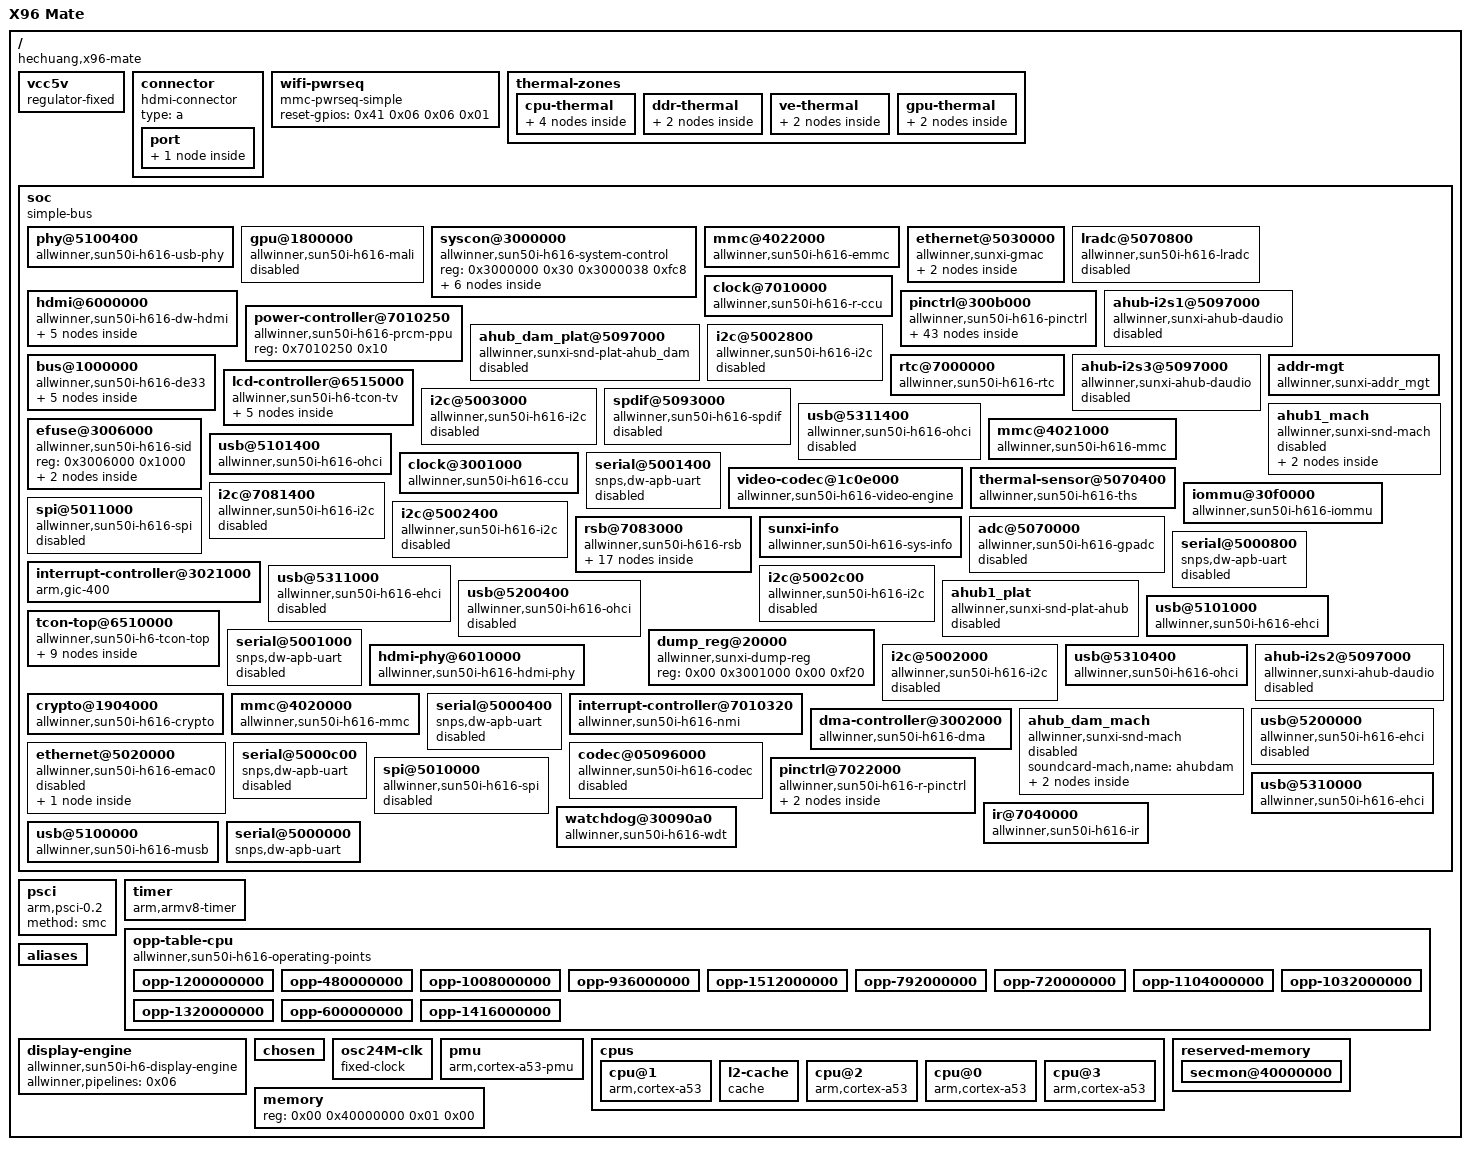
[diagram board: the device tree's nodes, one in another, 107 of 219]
/dts-v1/;

/ {
	#address-cells = <0x02>;
	model = "X96 Mate";
	serial-number = "32c0500063aacc40";
	#size-cells = <0x02>;
	interrupt-parent = <0x01>;
	compatible = "hechuang,x96-mate\0allwinner,sun50i-h616";

	vcc5v {
		regulator-max-microvolt = <0x4c4b40>;
		regulator-always-on;
		regulator-min-microvolt = <0x4c4b40>;
		regulator-name = "vcc-5v";
		compatible = "regulator-fixed";
		phandle = <0x33>;
	};

	connector {
		type = "a";
		compatible = "hdmi-connector";

		port {

			endpoint {
				remote-endpoint = <0x36>;
				phandle = <0x27>;
			};
		};
	};

	wifi-pwrseq {
		reset-gpios = <0x41 0x06 0x06 0x01>;
		compatible = "mmc-pwrseq-simple";
		phandle = <0xa9>;
	};

	thermal-zones {

		cpu-thermal {
			polling-delay = <0x3e8>;
			polling-delay-passive = <0x1f4>;
			thermal-sensors = <0x34 0x02>;
			sustainable-power = <0x3e8>;

			trips {

				cpu-trip-2 {
					temperature = <0x1adb0>;
					hysteresis = <0x00>;
					type = "critical";
					phandle = <0xa5>;
				};

				cpu-trip-0 {
					temperature = <0xea60>;
					hysteresis = <0x00>;
					type = "passive";
					phandle = <0xa3>;
				};

				cpu-trip-1 {
					temperature = <0x11170>;
					hysteresis = <0x00>;
					type = "passive";
					phandle = <0xa4>;
				};
			};
		};

		ddr-thermal {
			polling-delay = <0x00>;
			polling-delay-passive = <0x00>;
			thermal-sensors = <0x34 0x03>;

			trips {

				ddr-trip-0 {
					temperature = <0x1adb0>;
					hysteresis = <0x00>;
					type = "critical";
					phandle = <0xa8>;
				};
			};
		};

		ve-thermal {
			polling-delay = <0x00>;
			polling-delay-passive = <0x00>;
			thermal-sensors = <0x34 0x01>;

			trips {

				ve-trip-0 {
					temperature = <0x1adb0>;
					hysteresis = <0x00>;
					type = "critical";
					phandle = <0xa7>;
				};
			};
		};

		gpu-thermal {
			polling-delay = <0x3e8>;
			polling-delay-passive = <0x1f4>;
			thermal-sensors = <0x34 0x00>;
			sustainable-power = <0x44c>;

			trips {

				gpu-trip-0 {
					temperature = <0x1adb0>;
					hysteresis = <0x00>;
					type = "critical";
					phandle = <0xa6>;
				};
			};
		};
	};

	soc {
		#address-cells = <0x01>;
		#size-cells = <0x01>;
		compatible = "simple-bus";
		ranges = <0x00 0x00 0x00 0x40000000>;

		phy@5100400 {
			clock-names = "usb0_phy\0usb1_phy\0usb2_phy\0usb3_phy\0pmu2_clk";
			reg-names = "phy_ctrl\0pmu0\0pmu1\0pmu2\0pmu3";
			resets = <0x02 0x26 0x02 0x27 0x02 0x28 0x02 0x29>;
			clocks = <0x02 0x61 0x02 0x63 0x02 0x65 0x02 0x67 0x02 0x6e>;
			#phy-cells = <0x01>;
			compatible = "allwinner,sun50i-h616-usb-phy";
			status = "okay";
			reg = <0x5100400 0x24 0x5101800 0x14 0x5200800 0x14 0x5310800 0x14 0x5311800 0x14>;
			phandle = <0x24>;
			reset-names = "usb0_reset\0usb1_reset\0usb2_reset\0usb3_reset";
		};

		gpu@1800000 {
			power-domains = <0x0e 0x02>;
			clock-names = "core\0bus";
			resets = <0x02 0x03>;
			interrupts = <0x00 0x5f 0x04 0x00 0x60 0x04 0x00 0x61 0x04>;
			clocks = <0x02 0x23 0x02 0x24>;
			compatible = "allwinner,sun50i-h616-mali\0arm,mali-bifrost";
			status = "disabled";
			interrupt-names = "job\0mmu\0gpu";
			reg = <0x1800000 0x40000>;
			phandle = <0x39>;
		};

		syscon@3000000 {
			#address-cells = <0x01>;
			#size-cells = <0x01>;
			compatible = "allwinner,sun50i-h616-system-control";
			ranges;
			reg = <0x3000000 0x30 0x3000038 0xfc8>;
			phandle = <0x1a>;

			sram@1a00000 {
				#address-cells = <0x01>;
				#size-cells = <0x01>;
				compatible = "mmio-sram";
				ranges = <0x00 0x1a00000 0x200000>;
				reg = <0x1a00000 0x200000>;
				phandle = <0x3e>;

				sram-section@0 {
					compatible = "allwinner,sun50i-h616-sram-c1";
					reg = <0x00 0x200000>;
					phandle = <0x10>;
				};
			};

			sram@100000 {
				#address-cells = <0x01>;
				#size-cells = <0x01>;
				compatible = "mmio-sram";
				ranges = <0x00 0x100000 0x18000>;
				reg = <0x100000 0x18000>;
				phandle = <0x3b>;

				scpi-sram@17c00 {
					compatible = "arm,scp-shmem";
					reg = <0x17c00 0x200>;
					phandle = <0x3c>;
				};
			};

			sram@28000 {
				#address-cells = <0x01>;
				#size-cells = <0x01>;
				compatible = "mmio-sram";
				ranges = <0x00 0x28000 0x30000>;
				reg = <0x28000 0x30000>;
				phandle = <0x3d>;

				sram-section@0 {
					compatible = "allwinner,sun50i-h616-sram-c\0allwinner,sun50i-a64-sram-c";
					reg = <0x00 0x1e000>;
					phandle = <0x0b>;
				};
			};
		};

		mmc@4022000 {
			mmc-ddr-3_3v;
			pinctrl-names = "default";
			#address-cells = <0x01>;
			pinctrl-0 = <0x15>;
			clock-names = "ahb\0mmc";
			cap-sd-highspeed;
			vqmmc-supply = <0x16>;
			mmc-hs200-1_8v;
			bus-width = <0x08>;
			non-removable;
			resets = <0x02 0x10>;
			cap-sdio-irq;
			interrupts = <0x00 0x25 0x04>;
			clocks = <0x02 0x41 0x02 0x3e>;
			#size-cells = <0x00>;
			vmmc-supply = <0x13>;
			cap-mmc-hw-reset;
			mmc-ddr-1_8v;
			compatible = "allwinner,sun50i-h616-emmc\0allwinner,sun50i-a100-emmc";
			status = "okay";
			reg = <0x4022000 0x1000>;
			phandle = <0x68>;
			max-frequency = <0x8f0d180>;
			cap-mmc-highspeed;
			reset-names = "ahb";
		};

		ethernet@5030000 {
			rx-delay = <0x1f>;
			gmac-power1;
			pinctrl-names = "default";
			phy-supply = <0x1d>;
			phy-mode = "rmii";
			phy-rst;
			tx-delay = <0x07>;
			pinctrl-0 = <0x1b>;
			clock-names = "bus-emac1\0emac-25m";
			reg-names = "gmac1_reg\0ephy_reg";
			local-mac-address = [02 00 63 aa cc 40];
			resets = <0x02 0x1f>;
			interrupts = <0x00 0x0f 0x04>;
			clocks = <0x02 0x53 0x02 0x51>;
			gmac-power2;
			gmac-power0;
			compatible = "allwinner,sunxi-gmac";
			status = "okay";
			interrupt-names = "gmacirq";
			reg = <0x5030000 0x10000 0x3000034 0x04>;
			phandle = <0x78>;
			allwinner,tx-delay-ps = <0x2bc>;
			phy-handle = <0x1c>;
			reset-names = "stmmaceth";
			allwinner,rx-delay-ps = <0xc1c>;

			mdio {
				#address-cells = <0x01>;
				#size-cells = <0x00>;
				compatible = "ethernet-phy-ieee802.3-c22";
				phandle = <0x79>;

				ethernet-phy@1 {
					compatible = "ethernet-phy-ieee802.3-c22";
					reg = <0x01>;
					phandle = <0x1c>;
				};
			};
		};

		lradc@5070800 {
			resets = <0x02 0x3b>;
			interrupts = <0x00 0x14 0x04>;
			clocks = <0x02 0x71>;
			compatible = "allwinner,sun50i-h616-lradc\0allwinner,sun50i-r329-lradc";
			status = "disabled";
			reg = <0x5070800 0x400>;
			phandle = <0x7c>;
		};

		hdmi@6000000 {
			reg-io-width = <0x01>;
			phy-names = "phy";
			clock-names = "iahb\0isfr\0tmds\0cec\0hdcp\0hdcp-bus";
			hvcc-supply = <0x16>;
			resets = <0x02 0x33 0x02 0x3a>;
			interrupts = <0x00 0x3f 0x04>;
			clocks = <0x02 0x75 0x02 0x73 0x02 0x72 0x02 0x74 0x02 0x7e 0x02 0x7f>;
			#sound-dai-cells = <0x00>;
			compatible = "allwinner,sun50i-h616-dw-hdmi\0allwinner,sun50i-h6-dw-hdmi";
			status = "okay";
			phys = <0x25>;
			reg = <0x6000000 0x10000>;
			phandle = <0x23>;
			reset-names = "ctrl\0hdcp";

			ports {
				#address-cells = <0x01>;
				#size-cells = <0x00>;

				port@0 {
					reg = <0x00>;
					phandle = <0x8d>;

					endpoint {
						remote-endpoint = <0x26>;
						phandle = <0x2b>;
					};
				};

				port@1 {
					reg = <0x01>;
					phandle = <0x8e>;

					endpoint {
						remote-endpoint = <0x27>;
						phandle = <0x36>;
					};
				};
			};
		};

		clock@7010000 {
			#reset-cells = <0x01>;
			clock-names = "hosc\0losc\0iosc\0pll-periph";
			clocks = <0x11 0x0f 0x00 0x0f 0x02 0x02 0x04>;
			#clock-cells = <0x01>;
			compatible = "allwinner,sun50i-h616-r-ccu";
			reg = <0x7010000 0x210>;
			phandle = <0x2f>;
		};

		pinctrl@300b000 {
			clock-names = "apb\0hosc\0losc";
			gpio-controller;
			interrupts = <0x00 0x33 0x04 0x00 0x34 0x04 0x00 0x35 0x04 0x00 0x2b 0x04 0x00 0x36 0x04 0x00 0x37 0x04 0x00 0x38 0x04 0x00 0x39 0x04>;
			clocks = <0x02 0x1a 0x11 0x0f 0x00>;
			compatible = "allwinner,sun50i-h616-pinctrl";
			#interrupt-cells = <0x03>;
			reg = <0x300b000 0x400>;
			phandle = <0x41>;
			#gpio-cells = <0x03>;
			interrupt-controller;

			i2c4-ph-pins {
				function = "i2c4";
				pins = "PH6\0PH7";
				phandle = <0x4a>;
			};

			pwm2-ph-pin {
				function = "pwm2";
				pins = "PH2";
				phandle = <0x50>;
			};

			pwm3-ph-pin {
				function = "pwm3";
				pins = "PH0";
				phandle = <0x51>;
			};

			uart2-pg-pins {
				function = "uart2";
				pins = "PG15\0PG16";
				phandle = <0x5c>;
			};

			pwm4-ph-pin {
				function = "pwm4";
				pins = "PH1";
				phandle = <0x52>;
			};

			spi1-cs0-pin {
				function = "spi1";
				pins = "PH5";
				phandle = <0x57>;
			};

			i2c1-pi-pins {
				function = "i2c1";
				pins = "PI7\0PI8";
				phandle = <0x43>;
			};

			i2c4-pg-pins {
				function = "i2c4";
				pins = "PG15\0PG16";
				phandle = <0x49>;
			};

			uart5-pins {
				function = "uart5";
				pins = "PH2\0PH3";
				phandle = <0x63>;
			};

			rmii-pins {
				function = "emac1";
				pins = "PA0\0PA1\0PA2\0PA3\0PA4\0PA5\0PA6\0PA7\0PA8\0PA9";
				drive-strength = <0x28>;
				phandle = <0x1b>;
			};

			pwm1-pi-pin {
				function = "pwm1";
				pins = "PI11";
				phandle = <0x4f>;
			};

			pwm5-pin {
				function = "pwm5";
				pins = "PA12";
				phandle = <0x53>;
				bias-pull-up;
			};

			mmc2-pins {
				function = "mmc2";
				pins = "PC0\0PC1\0PC5\0PC6\0PC8\0PC9\0PC10\0PC11\0PC13\0PC14\0PC15\0PC16";
				drive-strength = <0x1e>;
				phandle = <0x15>;
				bias-pull-up;
			};

			uart3-pi-pins {
				function = "uart3";
				pins = "PI9\0PI10";
				phandle = <0x60>;
			};

			uart2-pg-rts-cts-pins {
				function = "uart2";
				pins = "PG17\0PG18";
				phandle = <0x5d>;
			};

			spi1-cs1-pin {
				function = "spi1";
				pins = "PH9";
				phandle = <0x58>;
			};

			ir-rx-pin {
				function = "ir_rx";
				pins = "PH10";
				phandle = <0x30>;
			};

			mmc1-pins {
				function = "mmc1";
				pins = "PG0\0PG1\0PG2\0PG3\0PG4\0PG5";
				drive-strength = <0x1e>;
				phandle = <0x14>;
				bias-pull-up;
			};

			i2c3-ph-pins {
				function = "i2c3";
				pins = "PH4\0PH5";
				phandle = <0x48>;
			};

			uart1-rts-cts-pins {
				function = "uart1";
				pins = "PG8\0PG9";
				phandle = <0x5a>;
			};

			i2c3-pa-pins {
				function = "i2c3";
				pins = "PA10\0PA11";
				phandle = <0x46>;
				bias-pull-up;
			};

			rgmii-pins {
				function = "emac0";
				pins = "PI0\0PI1\0PI2\0PI3\0PI4\0PI5\0PI7\0PI8\0PI9\0PI10\0PI11\0PI12\0PI13\0PI14\0PI15";
				drive-strength = <0x28>;
				phandle = <0x42>;
			};

			mmc0-pins {
				function = "mmc0";
				pins = "PF0\0PF1\0PF2\0PF3\0PF4\0PF5";
				drive-strength = <0x1e>;
				phandle = <0x12>;
				bias-pull-up;
			};

			spi0-cs0-pin {
				function = "spi0";
				pins = "PC3";
				phandle = <0x55>;
			};

			i2c3-pg-pins {
				function = "i2c3";
				pins = "PG17\0PG18";
				phandle = <0x47>;
			};

			x32clk-fanout-pin {
				function = "clock";
				pins = "PG10";
				phandle = <0x64>;
			};

			spi1-pins {
				function = "spi1";
				pins = "PH6\0PH7\0PH8";
				phandle = <0x56>;
			};

			i2s3-pins {
				function = "i2s3";
				pins = "PH5\0PH6\0PH7\0PH8\0PH9";
				phandle = <0x4c>;
			};

			uart2-ph-rts-cts-pins {
				function = "uart2";
				pins = "PH7\0PH8";
				phandle = <0x5f>;
			};

			pwm1-pg-pin {
				function = "pwm1";
				pins = "PG19";
				phandle = <0x4d>;
			};

			i2c2-pi-pins {
				function = "i2c2";
				pins = "PI9\0PI10";
				phandle = <0x45>;
			};

			uart4-pi-rts-cts-pins {
				function = "uart4";
				pins = "PI15\0PI16";
				phandle = <0x62>;
			};

			i2c0-pins {
				function = "i2c0";
				pins = "PI5\0PI6";
				phandle = <0x19>;
			};

			uart2-pi-pins {
				function = "uart2";
				pins = "PI5\0PI6";
				phandle = <0x5b>;
			};

			uart0-ph-pins {
				function = "uart0";
				pins = "PH0\0PH1";
				phandle = <0x18>;
			};

			uart1-pins {
				function = "uart1";
				pins = "PG6\0PG7";
				phandle = <0x59>;
			};

			spi0-pins {
				function = "spi0";
				pins = "PC0\0PC2\0PC4";
				phandle = <0x54>;
			};

			i2s2-pins {
				function = "i2s2";
				pins = "PG10\0PG11\0PG12\0PG13\0PG14";
				phandle = <0x4b>;
			};

			i2c2-ph-pins {
				function = "i2c2";
				pins = "PH2\0PH3";
				phandle = <0x44>;
			};

			uart4-pi-pins {
				function = "uart4";
				pins = "PI13\0PI14";
				phandle = <0x61>;
			};

			uart2-ph-pins {
				function = "uart2";
				pins = "PH5\0PH6";
				phandle = <0x5e>;
			};

			pwm1-ph-pin {
				function = "pwm1";
				pins = "PH3";
				phandle = <0x4e>;
			};

			spdif-tx-pin {
				function = "spdif";
				pins = "PH4";
				phandle = <0x1e>;
			};
		};

		ahub-i2s1@5097000 {
			daudio_master = <0x04>;
			clock-names = "apb\0audio-codec-1x\0audio-codec-4x\0audio-hub";
			signal_inversion = <0x01>;
			mclk_div = <0x01>;
			clocks = <0x02 0x5f 0x02 0x5b 0x02 0x5c 0x02 0x5e>;
			pinconfig = <0x00>;
			#sound-dai-cells = <0x00>;
			frametype = <0x00>;
			compatible = "allwinner,sunxi-ahub-daudio";
			audio_format = <0x01>;
			slot_width_select = <0x20>;
			status = "disabled";
			tdm_num = <0x01>;
			reg = <0x5097000 0xadf>;
			phandle = <0x81>;
			tdm_config = <0x01>;
			pcm_lrck_period = <0x20>;
		};

		power-controller@7010250 {
			#power-domain-cells = <0x01>;
			compatible = "allwinner,sun50i-h616-prcm-ppu";
			reg = <0x7010250 0x10>;
			phandle = <0x0e>;
		};

		ahub_dam_plat@5097000 {
			clock-names = "clk_pll_audio\0clk_pll_audio_4x\0clk_audio_hub\0clk_bus_audio_hub";
			resets = <0x02 0x25>;
			clocks = <0x02 0x5b 0x02 0x5c 0x02 0x5e 0x02 0x5f>;
			#sound-dai-cells = <0x00>;
			compatible = "allwinner,sunxi-snd-plat-ahub_dam";
			status = "disabled";
			reg = <0x5097000 0x1000>;
			phandle = <0x20>;
		};

		bus@1000000 {
			#address-cells = <0x01>;
			allwinner,sram = <0x0b 0x01>;
			#size-cells = <0x01>;
			compatible = "allwinner,sun50i-h616-de33\0allwinner,sun50i-a64-de2";
			ranges = <0x00 0x1000000 0x400000>;
			reg = <0x1000000 0x400000>;

			mixer@100000 {
				clock-names = "bus\0mod";
				resets = <0x0c 0x00>;
				clocks = <0x0c 0x00 0x0c 0x06>;
				compatible = "allwinner,sun50i-h616-de33-mixer-0";
				reg = <0x100000 0x100000 0x8100 0x40 0x280000 0x20000>;
				phandle = <0x06>;

				ports {
					#address-cells = <0x01>;
					#size-cells = <0x00>;

					port@1 {
						reg = <0x01>;
						phandle = <0x38>;

						endpoint {
							remote-endpoint = <0x0d>;
							phandle = <0x28>;
						};
					};
				};
			};

			clock@8000 {
				#reset-cells = <0x01>;
				clock-names = "mod\0bus";
				resets = <0x02 0x01>;
				clocks = <0x02 0x1d 0x02 0x1e>;
				#clock-cells = <0x01>;
				compatible = "allwinner,sun50i-h616-de33-clk";
				reg = <0x8000 0x100>;
				phandle = <0x0c>;
			};
		};

		i2c@5002800 {
			#address-cells = <0x01>;
			resets = <0x02 0x19>;
			interrupts = <0x00 0x08 0x04>;
			clocks = <0x02 0x4a>;
			#size-cells = <0x00>;
			dma-names = "rx\0tx";
			compatible = "allwinner,sun50i-h616-i2c\0allwinner,sun8i-v536-i2c\0allwinner,sun6i-a31-i2c";
			status = "disabled";
			reg = <0x5002800 0x400>;
			phandle = <0x71>;
			dmas = <0x17 0x2d 0x17 0x2d>;
		};

		rtc@7000000 {
			clock-names = "bus\0hosc\0pll-32k";
			interrupts = <0x00 0x68 0x04>;
			clocks = <0x2f 0x0e 0x11 0x02 0x80>;
			#clock-cells = <0x01>;
			compatible = "allwinner,sun50i-h616-rtc";
			reg = <0x7000000 0x400>;
			phandle = <0x0f>;
		};

		ahub-i2s3@5097000 {
			daudio_master = <0x04>;
			clock-names = "apb\0audio-codec-1x\0audio-codec-4x\0audio-hub";
			signal_inversion = <0x01>;
			mclk_div = <0x04>;
			clocks = <0x02 0x5f 0x02 0x5b 0x02 0x5c 0x02 0x5e>;
			pinconfig = <0x01>;
			frametype = <0x00>;
			compatible = "allwinner,sunxi-ahub-daudio";
			audio_format = <0x01>;
			slot_width_select = <0x20>;
			status = "disabled";
			tdm_num = <0x03>;
			reg = <0x5097000 0xadf>;
			phandle = <0x83>;
			tdm_config = <0x01>;
			pcm_lrck_period = <0x20>;
		};

		addr-mgt {
			compatible = "allwinner,sunxi-addr_mgt";
			status = "okay";
			type_addr_eth = <0x02>;
			type_addr_wifi = <0x02>;
			phandle = <0xa2>;
			type_addr_bt = <0x02>;
		};

		lcd-controller@6515000 {
			clock-names = "ahb\0tcon-ch1";
			resets = <0x02 0x36>;
			interrupts = <0x00 0x42 0x04>;
			clocks = <0x02 0x79 0x2c 0x00>;
			compatible = "allwinner,sun50i-h6-tcon-tv\0allwinner,sun8i-r40-tcon-tv";
			reg = <0x6515000 0x1000>;
			phandle = <0x93>;
			reset-names = "lcd";

			ports {
				#address-cells = <0x01>;
				#size-cells = <0x00>;

				port@0 {
					reg = <0x00>;
					phandle = <0x94>;

					endpoint {
						remote-endpoint = <0x2d>;
						phandle = <0x29>;
					};
				};

				port@1 {
					#address-cells = <0x01>;
					#size-cells = <0x00>;
					reg = <0x01>;
					phandle = <0x95>;

					endpoint@1 {
						remote-endpoint = <0x2e>;
						reg = <0x01>;
						phandle = <0x2a>;
					};
				};
			};
		};

		i2c@5003000 {
			#address-cells = <0x01>;
			resets = <0x02 0x1b>;
			interrupts = <0x00 0x0a 0x04>;
			clocks = <0x02 0x4c>;
			#size-cells = <0x00>;
			dma-names = "rx\0tx";
			compatible = "allwinner,sun50i-h616-i2c\0allwinner,sun8i-v536-i2c\0allwinner,sun6i-a31-i2c";
			status = "disabled";
			reg = <0x5003000 0x400>;
			phandle = <0x73>;
			dmas = <0x17 0x2f 0x17 0x2f>;
		};

		spdif@5093000 {
			pinctrl-names = "default";
			pinctrl-0 = <0x1e>;
			clock-names = "apb\0spdif";
			resets = <0x02 0x22>;
			interrupts = <0x00 0x15 0x04>;
			clocks = <0x02 0x58 0x02 0x57>;
			dma-names = "tx";
			#sound-dai-cells = <0x00>;
			compatible = "allwinner,sun50i-h616-spdif";
			status = "disabled";
			reg = <0x5093000 0x400>;
			phandle = <0x7a>;
			dmas = <0x17 0x02>;
		};

		usb@5311400 {
			phy-names = "usb";
			resets = <0x02 0x2d>;
			interrupts = <0x00 0x21 0x04>;
			clocks = <0x02 0x6b 0x02 0x66>;
			compatible = "allwinner,sun50i-h616-ohci\0generic-ohci";
			status = "disabled";
			phys = <0x24 0x03>;
			reg = <0x5311400 0x100>;
			phandle = <0x8c>;
		};

		ahub1_mach {
			soundcard-mach,slot-num = <0x02>;
			soundcard-mach,slot-width = <0x20>;
			compatible = "allwinner,sunxi-snd-mach";
			status = "disabled";
			soundcard-mach,frame-master = <0x21>;
			phandle = <0x7f>;
			soundcard-mach,name = "HDMI";
			soundcard-mach,format = "i2s";
			soundcard-mach,bitclock-master = <0x21>;

			soundcard-mach,codec {
				phandle = <0x80>;
				sound-dai = <0x23>;
			};

			soundcard-mach,cpu {
				soundcard-mach,mclk-fs = <0x00>;
				soundcard-mach,pll-fs = <0x04>;
				phandle = <0x21>;
				sound-dai = <0x22>;
			};
		};

		efuse@3006000 {
			#address-cells = <0x01>;
			#size-cells = <0x01>;
			compatible = "allwinner,sun50i-h616-sid\0allwinner,sun50i-a64-sid";
			reg = <0x3006000 0x1000>;
			phandle = <0x3f>;

			thermal-sensor-calibration@14 {
				reg = <0x14 0x08>;
				phandle = <0x1f>;
			};

			cpu-speed-grade@0 {
				reg = <0x00 0x02>;
				phandle = <0x35>;
			};
		};

		mmc@4021000 {
			mmc-ddr-3_3v;
			pinctrl-names = "default";
			#address-cells = <0x01>;
			pinctrl-0 = <0x14>;
			clock-names = "ahb\0mmc";
			cap-sd-highspeed;
			vqmmc-supply = <0x13>;
			bus-width = <0x04>;
			non-removable;
			resets = <0x02 0x0f>;
			cap-sdio-irq;
			interrupts = <0x00 0x24 0x04>;
			clocks = <0x02 0x40 0x02 0x3d>;
			#size-cells = <0x00>;
			vmmc-supply = <0x13>;
			keep-power-in-suspend;
			compatible = "allwinner,sun50i-h616-mmc\0allwinner,sun50i-a100-mmc";
			status = "okay";
			mmc-pwrseq = <0xa9>;
			reg = <0x4021000 0x1000>;
			phandle = <0x67>;
			max-frequency = <0x2faf080>;
			cap-mmc-highspeed;
			reset-names = "ahb";
		};

		usb@5101400 {
			phy-names = "usb";
			resets = <0x02 0x2a>;
			interrupts = <0x00 0x1b 0x04>;
			clocks = <0x02 0x68 0x02 0x60>;
			compatible = "allwinner,sun50i-h616-ohci\0generic-ohci";
			status = "okay";
			phys = <0x24 0x00>;
			reg = <0x5101400 0x100>;
			phandle = <0x86>;
		};

		clock@3001000 {
			#reset-cells = <0x01>;
			clock-names = "hosc\0losc\0iosc";
			clocks = <0x11 0x0f 0x00 0x0f 0x02>;
			#clock-cells = <0x01>;
			compatible = "allwinner,sun50i-h616-ccu";
			reg = <0x3001000 0x1000>;
			phandle = <0x02>;
		};

		serial@5001400 {
			reg-io-width = <0x04>;
			resets = <0x02 0x16>;
			interrupts = <0x00 0x05 0x04>;
			clocks = <0x02 0x47>;
			dma-names = "tx\0rx";
			compatible = "snps,dw-apb-uart";
			status = "disabled";
			reg = <0x5001400 0x400>;
			phandle = <0x6e>;
			dmas = <0x17 0x13 0x17 0x13>;
			reg-shift = <0x02>;
		};

		video-codec@1c0e000 {
			clock-names = "ahb\0mod\0ram";
			allwinner,sram = <0x10 0x01>;
			resets = <0x02 0x05>;
			interrupts = <0x00 0x5d 0x04>;
			clocks = <0x02 0x29 0x02 0x28 0x02 0x33>;
			compatible = "allwinner,sun50i-h616-video-engine";
			reg = <0x1c0e000 0x2000>;
		};

		thermal-sensor@5070400 {
			nvmem-cells = <0x1f>;
			clock-names = "bus";
			allwinner,sram = <0x1a>;
			resets = <0x02 0x21>;
			interrupts = <0x00 0x13 0x04>;
			clocks = <0x02 0x56>;
			#thermal-sensor-cells = <0x01>;
			compatible = "allwinner,sun50i-h616-ths";
			nvmem-cell-names = "calibration";
			reg = <0x5070400 0x400>;
			phandle = <0x34>;
		};

		i2c@7081400 {
			pinctrl-names = "default";
			#address-cells = <0x01>;
			pinctrl-0 = <0x31>;
			resets = <0x2f 0x04>;
			interrupts = <0x00 0x69 0x04>;
			clocks = <0x2f 0x08>;
			#size-cells = <0x00>;
			dma-names = "rx\0tx";
			compatible = "allwinner,sun50i-h616-i2c\0allwinner,sun8i-v536-i2c\0allwinner,sun6i-a31-i2c";
			status = "disabled";
			reg = <0x7081400 0x400>;
			phandle = <0x99>;
			dmas = <0x17 0x30 0x17 0x30>;
		};

		iommu@30f0000 {
			resets = <0x02 0x0b>;
			interrupts = <0x00 0x3d 0x04>;
			clocks = <0x02 0x30>;
			#iommu-cells = <0x01>;
			compatible = "allwinner,sun50i-h616-iommu\0allwinner,sun50i-h6-iommu";
			reg = <0x30f0000 0x10000>;
			phandle = <0x65>;
		};

		i2c@5002400 {
			#address-cells = <0x01>;
			resets = <0x02 0x18>;
			interrupts = <0x00 0x07 0x04>;
			clocks = <0x02 0x49>;
			#size-cells = <0x00>;
			dma-names = "rx\0tx";
			compatible = "allwinner,sun50i-h616-i2c\0allwinner,sun8i-v536-i2c\0allwinner,sun6i-a31-i2c";
			status = "disabled";
			reg = <0x5002400 0x400>;
			phandle = <0x70>;
			dmas = <0x17 0x2c 0x17 0x2c>;
		};

		rsb@7083000 {
			pinctrl-names = "default";
			#address-cells = <0x01>;
			pinctrl-0 = <0x32>;
			resets = <0x2f 0x07>;
			interrupts = <0x00 0x6d 0x04>;
			clocks = <0x2f 0x0d>;
			#size-cells = <0x00>;
			clock-frequency = <0x2dc6c0>;
			compatible = "allwinner,sun50i-h616-rsb\0allwinner,sun8i-a23-rsb";
			status = "okay";
			reg = <0x7083000 0x400>;
			phandle = <0x9a>;

			pmic@745 {
				vina-supply = <0x33>;
				vinb-supply = <0x33>;
				vinc-supply = <0x33>;
				vind-supply = <0x33>;
				vine-supply = <0x33>;
				bldoin-supply = <0x33>;
				compatible = "x-powers,axp305\0x-powers,axp805\0x-powers,axp806";
				#interrupt-cells = <0x01>;
				reg = <0x745>;
				phandle = <0x9b>;
				cldoin-supply = <0x33>;
				aldoin-supply = <0x33>;
				x-powers,self-working-mode;
				interrupt-controller;

				regulators {

					aldo3 {
						regulator-max-microvolt = <0x325aa0>;
						regulator-min-microvolt = <0x325aa0>;
						regulator-name = "vcc3v3-ext2";
						status = "disabled";
						phandle = <0x9d>;
					};

					cldo2 {
					};

					dcdcc {
						regulator-max-microvolt = <0xf1b30>;
						regulator-always-on;
						regulator-min-microvolt = <0xc5c10>;
						regulator-name = "vdd-gpu-sys";
						phandle = <0x9f>;
					};

					aldo1 {
						regulator-max-microvolt = <0x325aa0>;
						regulator-always-on;
						regulator-min-microvolt = <0x325aa0>;
						regulator-name = "vcc-sys";
						phandle = <0x1d>;
					};

					dcdca {
						regulator-max-microvolt = <0x10c8e0>;
						regulator-always-on;
						regulator-min-microvolt = <0xc5c10>;
						regulator-name = "vdd-cpu";
						phandle = <0x05>;
					};

					bldo3 {
					};

					bldo1 {
						regulator-max-microvolt = <0x1b7740>;
						regulator-always-on;
						regulator-min-microvolt = <0x1b7740>;
						regulator-name = "vcc1v8";
						phandle = <0x16>;
					};

					sw {
					};

					cldo3 {
					};

					dcdcd {
						regulator-max-microvolt = <0x14c080>;
						regulator-always-on;
						regulator-min-microvolt = <0x14c080>;
						regulator-name = "vdd-dram";
						phandle = <0xa0>;
					};

					aldo2 {
						regulator-max-microvolt = <0x325aa0>;
						regulator-min-microvolt = <0x325aa0>;
						regulator-name = "vcc3v3-ext";
						status = "disabled";
						phandle = <0x9c>;
					};

					cldo1 {
						regulator-max-microvolt = <0x2625a0>;
						regulator-min-microvolt = <0x2625a0>;
						regulator-name = "vcc2v5";
					};

					bldo4 {
					};

					bldo2 {
						regulator-max-microvolt = <0x1b7740>;
						regulator-min-microvolt = <0x1b7740>;
						regulator-name = "vcc1v8-2";
						status = "disabled";
						phandle = <0x9e>;
					};

					dcdce {
						regulator-max-microvolt = <0x325aa0>;
						regulator-always-on;
						regulator-min-microvolt = <0x325aa0>;
						regulator-name = "vcc-eth-mmc";
						phandle = <0x13>;
					};
				};
			};
		};

		sunxi-info {
			compatible = "allwinner,sun50i-h616-sys-info";
			status = "okay";
		};

		spi@5011000 {
			#address-cells = <0x01>;
			clock-names = "ahb\0mod";
			resets = <0x02 0x1d>;
			interrupts = <0x00 0x0d 0x04>;
			clocks = <0x02 0x50 0x02 0x4e>;
			#size-cells = <0x00>;
			dma-names = "rx\0tx";
			compatible = "allwinner,sun50i-h616-spi\0allwinner,sun8i-h3-spi";
			status = "disabled";
			reg = <0x5011000 0x1000>;
			phandle = <0x75>;
			dmas = <0x17 0x17 0x17 0x17>;
		};

		adc@5070000 {
			resets = <0x02 0x3c>;
			interrupts = <0x00 0x12 0x04>;
			clocks = <0x02 0x81>;
			#io-channel-cells = <0x01>;
			compatible = "allwinner,sun50i-h616-gpadc\0allwinner,sun20i-d1-gpadc";
			status = "disabled";
			reg = <0x5070000 0x400>;
			phandle = <0x7b>;
		};

		serial@5000800 {
			reg-io-width = <0x04>;
			resets = <0x02 0x13>;
			interrupts = <0x00 0x02 0x04>;
			clocks = <0x02 0x44>;
			dma-names = "tx\0rx";
			compatible = "snps,dw-apb-uart";
			status = "disabled";
			reg = <0x5000800 0x400>;
			phandle = <0x6b>;
			dmas = <0x17 0x10 0x17 0x10>;
			reg-shift = <0x02>;
		};

		interrupt-controller@3021000 {
			interrupts = <0x01 0x09 0xf04>;
			compatible = "arm,gic-400";
			#interrupt-cells = <0x03>;
			reg = <0x3021000 0x1000 0x3022000 0x2000 0x3024000 0x2000 0x3026000 0x2000>;
			phandle = <0x01>;
			interrupt-controller;
		};

		usb@5311000 {
			phy-names = "usb";
			resets = <0x02 0x2d 0x02 0x31>;
			interrupts = <0x00 0x20 0x04>;
			clocks = <0x02 0x6b 0x02 0x6f 0x02 0x66>;
			compatible = "allwinner,sun50i-h616-ehci\0generic-ehci";
			status = "disabled";
			phys = <0x24 0x03>;
			reg = <0x5311000 0x100>;
			phandle = <0x8b>;
		};

		i2c@5002c00 {
			#address-cells = <0x01>;
			resets = <0x02 0x1a>;
			interrupts = <0x00 0x09 0x04>;
			clocks = <0x02 0x4b>;
			#size-cells = <0x00>;
			dma-names = "rx\0tx";
			compatible = "allwinner,sun50i-h616-i2c\0allwinner,sun8i-v536-i2c\0allwinner,sun6i-a31-i2c";
			status = "disabled";
			reg = <0x5002c00 0x400>;
			phandle = <0x72>;
			dmas = <0x17 0x2e 0x17 0x2e>;
		};

		usb@5200400 {
			phy-names = "usb";
			resets = <0x02 0x2b>;
			interrupts = <0x00 0x1d 0x04>;
			clocks = <0x02 0x69 0x02 0x62>;
			compatible = "allwinner,sun50i-h616-ohci\0generic-ohci";
			status = "disabled";
			phys = <0x24 0x01>;
			reg = <0x5200400 0x100>;
			phandle = <0x88>;
		};

		ahub1_plat {
			capture_cma = <0x80>;
			rx_fifo_size = <0x80>;
			rx_pin = <0x00>;
			dma-names = "tx\0rx";
			#sound-dai-cells = <0x00>;
			compatible = "allwinner,sunxi-snd-plat-ahub";
			status = "disabled";
			tdm_num = <0x01>;
			phandle = <0x22>;
			dmas = <0x17 0x04 0x17 0x04>;
			playback_cma = <0x80>;
			tx_fifo_size = <0x80>;
			tx_pin = <0x00>;
			apb_num = <0x01>;
		};

		usb@5101000 {
			phy-names = "usb";
			resets = <0x02 0x2a 0x02 0x2e>;
			interrupts = <0x00 0x1a 0x04>;
			clocks = <0x02 0x68 0x02 0x6c 0x02 0x60>;
			compatible = "allwinner,sun50i-h616-ehci\0generic-ehci";
			status = "okay";
			phys = <0x24 0x00>;
			reg = <0x5101000 0x100>;
			phandle = <0x85>;
		};

		tcon-top@6510000 {
			clock-output-names = "tcon-top-tv0";
			clock-names = "bus\0tcon-tv0";
			resets = <0x02 0x35>;
			clocks = <0x02 0x76 0x02 0x77>;
			#clock-cells = <0x01>;
			compatible = "allwinner,sun50i-h6-tcon-top";
			reg = <0x6510000 0x1000>;
			phandle = <0x2c>;

			ports {
				#address-cells = <0x01>;
				#size-cells = <0x00>;

				port@0 {
					#address-cells = <0x01>;
					#size-cells = <0x00>;
					reg = <0x00>;
					phandle = <0x8f>;

					endpoint@0 {
						remote-endpoint = <0x28>;
						reg = <0x00>;
						phandle = <0x0d>;
					};
				};

				port@5 {
					reg = <0x05>;
					phandle = <0x92>;

					endpoint {
						remote-endpoint = <0x2b>;
						phandle = <0x26>;
					};
				};

				port@1 {
					#address-cells = <0x01>;
					#size-cells = <0x00>;
					reg = <0x01>;
					phandle = <0x90>;

					endpoint@2 {
						remote-endpoint = <0x29>;
						reg = <0x02>;
						phandle = <0x2d>;
					};
				};

				port@4 {
					#address-cells = <0x01>;
					#size-cells = <0x00>;
					reg = <0x04>;
					phandle = <0x91>;

					endpoint@0 {
						remote-endpoint = <0x2a>;
						reg = <0x00>;
						phandle = <0x2e>;
					};
				};
			};
		};

		serial@5001000 {
			reg-io-width = <0x04>;
			resets = <0x02 0x15>;
			interrupts = <0x00 0x04 0x04>;
			clocks = <0x02 0x46>;
			dma-names = "tx\0rx";
			compatible = "snps,dw-apb-uart";
			status = "disabled";
			reg = <0x5001000 0x400>;
			phandle = <0x6d>;
			dmas = <0x17 0x12 0x17 0x12>;
			reg-shift = <0x02>;
		};

		dump_reg@20000 {
			compatible = "allwinner,sunxi-dump-reg";
			status = "okay";
			reg = <0x00 0x3001000 0x00 0xf20>;
			phandle = <0xa1>;
		};

		hdmi-phy@6010000 {
			clock-names = "bus\0mod";
			resets = <0x02 0x34>;
			clocks = <0x02 0x75 0x02 0x73>;
			#phy-cells = <0x00>;
			compatible = "allwinner,sun50i-h616-hdmi-phy";
			reg = <0x6010000 0x10000>;
			phandle = <0x25>;
			reset-names = "phy";
		};

		i2c@5002000 {
			pinctrl-names = "default";
			#address-cells = <0x01>;
			pinctrl-0 = <0x19>;
			resets = <0x02 0x17>;
			interrupts = <0x00 0x06 0x04>;
			clocks = <0x02 0x48>;
			#size-cells = <0x00>;
			dma-names = "rx\0tx";
			compatible = "allwinner,sun50i-h616-i2c\0allwinner,sun8i-v536-i2c\0allwinner,sun6i-a31-i2c";
			status = "disabled";
			reg = <0x5002000 0x400>;
			phandle = <0x6f>;
			dmas = <0x17 0x2b 0x17 0x2b>;
		};

		usb@5310400 {
			phy-names = "usb";
			resets = <0x02 0x2c>;
			interrupts = <0x00 0x1f 0x04>;
			clocks = <0x02 0x6a 0x02 0x64>;
			compatible = "allwinner,sun50i-h616-ohci\0generic-ohci";
			status = "okay";
			phys = <0x24 0x02>;
			reg = <0x5310400 0x100>;
			phandle = <0x8a>;
		};

		ahub-i2s2@5097000 {
			daudio_master = <0x04>;
			clock-names = "apb\0audio-codec-1x\0audio-codec-4x\0audio-hub";
			signal_inversion = <0x01>;
			mclk_div = <0x04>;
			clocks = <0x02 0x5f 0x02 0x5b 0x02 0x5c 0x02 0x5e>;
			pinconfig = <0x01>;
			frametype = <0x00>;
			compatible = "allwinner,sunxi-ahub-daudio";
			audio_format = <0x01>;
			slot_width_select = <0x20>;
			status = "disabled";
			tdm_num = <0x02>;
			reg = <0x5097000 0xadf>;
			phandle = <0x82>;
			tdm_config = <0x01>;
			pcm_lrck_period = <0x20>;
		};

		crypto@1904000 {
			clock-names = "bus\0mod\0ram\0trng";
			resets = <0x02 0x04>;
			interrupts = <0x00 0x5b 0x04>;
			clocks = <0x02 0x27 0x02 0x26 0x02 0x34 0x0f 0x02>;
			compatible = "allwinner,sun50i-h616-crypto";
			reg = <0x1904000 0x800>;
			phandle = <0x3a>;
		};

		mmc@4020000 {
			mmc-ddr-3_3v;
			pinctrl-names = "default";
			#address-cells = <0x01>;
			pinctrl-0 = <0x12>;
			clock-names = "ahb\0mmc";
			cap-sd-highspeed;
			bus-width = <0x04>;
			resets = <0x02 0x0e>;
			cap-sdio-irq;
			interrupts = <0x00 0x23 0x04>;
			clocks = <0x02 0x3f 0x02 0x3c>;
			broken-cd;
			#size-cells = <0x00>;
			vmmc-supply = <0x13>;
			compatible = "allwinner,sun50i-h616-mmc\0allwinner,sun50i-a100-mmc";
			status = "okay";
			reg = <0x4020000 0x1000>;
			phandle = <0x66>;
			max-frequency = <0x8f0d180>;
			cap-mmc-highspeed;
			reset-names = "ahb";
		};

		serial@5000400 {
			reg-io-width = <0x04>;
			resets = <0x02 0x12>;
			interrupts = <0x00 0x01 0x04>;
			clocks = <0x02 0x43>;
			dma-names = "tx\0rx";
			compatible = "snps,dw-apb-uart";
			status = "disabled";
			reg = <0x5000400 0x400>;
			phandle = <0x6a>;
			dmas = <0x17 0x0f 0x17 0x0f>;
			reg-shift = <0x02>;
		};

		interrupt-controller@7010320 {
			interrupts = <0x00 0x67 0x04>;
			compatible = "allwinner,sun50i-h616-nmi\0allwinner,sun9i-a80-nmi";
			#interrupt-cells = <0x02>;
			reg = <0x7010320 0x0c>;
			phandle = <0x96>;
			interrupt-controller;
		};

		dma-controller@3002000 {
			clock-names = "bus\0mbus";
			resets = <0x02 0x06>;
			interrupts = <0x00 0x2a 0x04>;
			clocks = <0x02 0x2a 0x02 0x32>;
			dma-requests = <0x31>;
			compatible = "allwinner,sun50i-h616-dma\0allwinner,sun50i-a100-dma";
			reg = <0x3002000 0x1000>;
			phandle = <0x17>;
			dma-channels = <0x10>;
			#dma-cells = <0x01>;
		};

		ahub_dam_mach {
			compatible = "allwinner,sunxi-snd-mach";
			status = "disabled";
			phandle = <0x7e>;
			soundcard-mach,name = "ahubdam";

			soundcard-mach,codec {
			};

			soundcard-mach,cpu {
				sound-dai = <0x20>;
			};
		};

		usb@5200000 {
			phy-names = "usb";
			resets = <0x02 0x2b 0x02 0x2f>;
			interrupts = <0x00 0x1c 0x04>;
			clocks = <0x02 0x69 0x02 0x6d 0x02 0x62>;
			compatible = "allwinner,sun50i-h616-ehci\0generic-ehci";
			status = "disabled";
			phys = <0x24 0x01>;
			reg = <0x5200000 0x100>;
			phandle = <0x87>;
		};

		ethernet@5020000 {
			syscon = <0x1a>;
			clock-names = "stmmaceth";
			resets = <0x02 0x1e>;
			interrupts = <0x00 0x0e 0x04>;
			clocks = <0x02 0x52>;
			compatible = "allwinner,sun50i-h616-emac0\0allwinner,sun50i-a64-emac";
			status = "disabled";
			interrupt-names = "macirq";
			reg = <0x5020000 0x10000>;
			phandle = <0x76>;
			reset-names = "stmmaceth";

			mdio {
				#address-cells = <0x01>;
				#size-cells = <0x00>;
				compatible = "snps,dwmac-mdio";
				phandle = <0x77>;
			};
		};

		codec@05096000 {
			clock-names = "apb\0audio-codec-1x\0audio-codec-4x";
			resets = <0x02 0x24>;
			interrupts = <0x00 0x3a 0x04>;
			clocks = <0x02 0x5d 0x02 0x5b 0x02 0x5c>;
			dma-names = "tx";
			#sound-dai-cells = <0x00>;
			compatible = "allwinner,sun50i-h616-codec";
			status = "disabled";
			reg = <0x5096000 0x31c>;
			phandle = <0x7d>;
			dmas = <0x17 0x06>;
		};

		serial@5000c00 {
			reg-io-width = <0x04>;
			resets = <0x02 0x14>;
			interrupts = <0x00 0x03 0x04>;
			clocks = <0x02 0x45>;
			dma-names = "tx\0rx";
			compatible = "snps,dw-apb-uart";
			status = "disabled";
			reg = <0x5000c00 0x400>;
			phandle = <0x6c>;
			dmas = <0x17 0x11 0x17 0x11>;
			reg-shift = <0x02>;
		};

		spi@5010000 {
			#address-cells = <0x01>;
			clock-names = "ahb\0mod";
			resets = <0x02 0x1c>;
			interrupts = <0x00 0x0c 0x04>;
			clocks = <0x02 0x4f 0x02 0x4d>;
			#size-cells = <0x00>;
			dma-names = "rx\0tx";
			compatible = "allwinner,sun50i-h616-spi\0allwinner,sun8i-h3-spi";
			status = "disabled";
			reg = <0x5010000 0x1000>;
			phandle = <0x74>;
			dmas = <0x17 0x16 0x17 0x16>;
		};

		pinctrl@7022000 {
			clock-names = "apb\0hosc\0losc";
			gpio-controller;
			clocks = <0x2f 0x02 0x11 0x0f 0x00>;
			compatible = "allwinner,sun50i-h616-r-pinctrl";
			reg = <0x7022000 0x400>;
			phandle = <0x97>;
			#gpio-cells = <0x03>;

			r-rsb-pins {
				function = "s_rsb";
				pins = "PL0\0PL1";
				phandle = <0x32>;
			};

			r-i2c-pins {
				function = "s_i2c";
				pins = "PL0\0PL1";
				phandle = <0x31>;
			};
		};

		usb@5310000 {
			phy-names = "usb";
			resets = <0x02 0x2c 0x02 0x30>;
			interrupts = <0x00 0x1e 0x04>;
			clocks = <0x02 0x6a 0x02 0x6e 0x02 0x64>;
			compatible = "allwinner,sun50i-h616-ehci\0generic-ehci";
			status = "okay";
			phys = <0x24 0x02>;
			reg = <0x5310000 0x100>;
			phandle = <0x89>;
		};

		ir@7040000 {
			pinctrl-names = "default";
			pinctrl-0 = <0x30>;
			clock-names = "apb\0ir";
			resets = <0x2f 0x05>;
			interrupts = <0x00 0x6a 0x04>;
			clocks = <0x2f 0x09 0x2f 0x0b>;
			compatible = "allwinner,sun50i-h616-ir\0allwinner,sun6i-a31-ir";
			status = "okay";
			reg = <0x7040000 0x400>;
			phandle = <0x98>;
		};

		watchdog@30090a0 {
			interrupts = <0x00 0x32 0x04>;
			clocks = <0x11>;
			compatible = "allwinner,sun50i-h616-wdt\0allwinner,sun6i-a31-wdt";
			reg = <0x30090a0 0x20>;
			phandle = <0x40>;
		};

		usb@5100000 {
			phy-names = "usb";
			resets = <0x02 0x32>;
			interrupts = <0x00 0x19 0x04>;
			clocks = <0x02 0x70>;
			extcon = <0x24 0x00>;
			compatible = "allwinner,sun50i-h616-musb\0allwinner,sun8i-h3-musb";
			status = "okay";
			interrupt-names = "mc";
			phys = <0x24 0x00>;
			reg = <0x5100000 0x400>;
			phandle = <0x84>;
			dr_mode = "host";
		};

		serial@5000000 {
			reg-io-width = <0x04>;
			pinctrl-names = "default";
			pinctrl-0 = <0x18>;
			resets = <0x02 0x11>;
			interrupts = <0x00 0x00 0x04>;
			clocks = <0x02 0x42>;
			dma-names = "tx\0rx";
			compatible = "snps,dw-apb-uart";
			status = "okay";
			reg = <0x5000000 0x400>;
			phandle = <0x69>;
			dmas = <0x17 0x0e 0x17 0x0e>;
			reg-shift = <0x02>;
		};
	};

	psci {
		method = "smc";
		compatible = "arm,psci-0.2";
	};

	timer {
		arm,no-tick-in-suspend;
		interrupts = <0x01 0x0d 0xf04 0x01 0x0e 0xf04 0x01 0x0b 0xf04 0x01 0x0a 0xf04>;
		compatible = "arm,armv8-timer";
	};

	opp-table-cpu {
		nvmem-cells = <0x35>;
		opp-shared;
		compatible = "allwinner,sun50i-h616-operating-points";
		phandle = <0x04>;

		opp-1200000000 {
			opp-microvolt-speed1 = <0xf9060>;
			opp-microvolt-speed4 = <0x10c8e0>;
			opp-hz = <0x00 0x47868c00>;
			opp-microvolt-speed2 = <0x100590>;
			opp-microvolt-speed0 = <0x100590>;
			opp-supported-hw = <0x3f>;
			opp-microvolt-speed5 = <0xf9060>;
			clock-latency-ns = <0x3b9b0>;
			opp-microvolt-speed3 = <0x100590>;
		};

		opp-480000000 {
			opp-microvolt = <0xdbba0>;
			opp-hz = <0x00 0x1c9c3800>;
			opp-supported-hw = <0x3f>;
			clock-latency-ns = <0x3b9b0>;
		};

		opp-1008000000 {
			opp-microvolt-speed1 = <0xe57e0>;
			opp-microvolt-speed4 = <0xf9060>;
			opp-hz = <0x00 0x3c14dc00>;
			opp-microvolt-speed2 = <0xe7ef0>;
			opp-microvolt-speed0 = <0xe7ef0>;
			opp-supported-hw = <0x3f>;
			opp-microvolt-speed5 = <0xdbba0>;
			clock-latency-ns = <0x3b9b0>;
			opp-microvolt-speed3 = <0xe7ef0>;
		};

		opp-936000000 {
			opp-microvolt = <0xdbba0>;
			opp-hz = <0x00 0x37ca3a00>;
			opp-supported-hw = <0x0d>;
			clock-latency-ns = <0x3b9b0>;
		};

		opp-1512000000 {
			opp-microvolt-speed1 = <0x10c8e0>;
			opp-hz = <0x00 0x5a1f4a00>;
			opp-supported-hw = <0x2a>;
			opp-microvolt-speed5 = <0x11b340>;
			clock-latency-ns = <0x3b9b0>;
			opp-microvolt-speed3 = <0x10c8e0>;
		};

		opp-792000000 {
			opp-microvolt-speed1 = <0xdbba0>;
			opp-microvolt-speed4 = <0xe57e0>;
			opp-hz = <0x00 0x2f34f600>;
			opp-supported-hw = <0x12>;
			clock-latency-ns = <0x3b9b0>;
		};

		opp-720000000 {
			opp-microvolt = <0xdbba0>;
			opp-hz = <0x00 0x2aea5400>;
			opp-supported-hw = <0x2d>;
			clock-latency-ns = <0x3b9b0>;
		};

		opp-1104000000 {
			opp-hz = <0x00 0x41cdb400>;
			opp-microvolt-speed2 = <0xf4240>;
			opp-microvolt-speed0 = <0xf4240>;
			opp-supported-hw = <0x2d>;
			opp-microvolt-speed5 = <0xe7ef0>;
			clock-latency-ns = <0x3b9b0>;
			opp-microvolt-speed3 = <0xf4240>;
		};

		opp-1032000000 {
			opp-microvolt = <0xdbba0>;
			opp-hz = <0x00 0x3d831200>;
			opp-supported-hw = <0x20>;
			clock-latency-ns = <0x3b9b0>;
		};

		opp-1320000000 {
			opp-microvolt = <0x10c8e0>;
			opp-hz = <0x00 0x4ead9a00>;
			opp-supported-hw = <0x1d>;
			clock-latency-ns = <0x3b9b0>;
		};

		opp-600000000 {
			opp-microvolt = <0xdbba0>;
			opp-hz = <0x00 0x23c34600>;
			opp-supported-hw = <0x12>;
			clock-latency-ns = <0x3b9b0>;
		};

		opp-1416000000 {
			opp-microvolt = <0x10c8e0>;
			opp-hz = <0x00 0x54667200>;
			opp-supported-hw = <0x2d>;
			clock-latency-ns = <0x3b9b0>;
		};
	};

	aliases {
		ethernet0 = "/soc/ethernet@5030000";
		serial0 = "/soc/serial@5000000";
	};

	display-engine {
		allwinner,pipelines = <0x06>;
		compatible = "allwinner,sun50i-h6-display-engine";
		status = "okay";
		phandle = <0x37>;
	};

	chosen {
		u-boot,version = "2024.01_armbian-2024.01-S866c-P4a40-H5afb-Vc4bf-B2eb2-R448a";
		linux,initrd-end = <0x00 0x49fff2f3>;
		bootargs = "root=UUID=70ea0aca-802e-4f61-9009-d5ea4aee7c46 rootwait rootfstype=ext4 splash=verbose console=ttyS0,115200 console=tty1 consoleblank=0 loglevel=1 ubootpart=64028123-01 usb-storage.quirks=0x2537:0x1066:u,0x2537:0x1068:u   cgroup_enable=memory";
		linux,initrd-start = <0x00 0x4919e000>;
		stdout-path = "serial0:115200n8";
	};

	osc24M-clk {
		clock-output-names = "osc24M";
		#clock-cells = <0x00>;
		clock-frequency = <0x16e3600>;
		compatible = "fixed-clock";
		phandle = <0x11>;
	};

	pmu {
		interrupt-affinity = <0x07 0x08 0x09 0x0a>;
		interrupts = <0x00 0x8c 0x04 0x00 0x8d 0x04 0x00 0x8e 0x04 0x00 0x8f 0x04>;
		compatible = "arm,cortex-a53-pmu";
	};

	cpus {
		#address-cells = <0x01>;
		#size-cells = <0x00>;

		cpu@1 {
			d-cache-line-size = <0x40>;
			clocks = <0x02 0x15>;
			i-cache-line-size = <0x40>;
			device_type = "cpu";
			compatible = "arm,cortex-a53";
			d-cache-size = <0x8000>;
			next-level-cache = <0x03>;
			i-cache-size = <0x8000>;
			reg = <0x01>;
			enable-method = "psci";
			phandle = <0x08>;
			d-cache-sets = <0x80>;
			operating-points-v2 = <0x04>;
			i-cache-sets = <0x100>;
			#cooling-cells = <0x02>;
		};

		l2-cache {
			cache-size = <0x40000>;
			cache-level = <0x02>;
			cache-sets = <0x100>;
			cache-unified;
			compatible = "cache";
			cache-line-size = <0x40>;
			phandle = <0x03>;
		};

		cpu@2 {
			d-cache-line-size = <0x40>;
			clocks = <0x02 0x15>;
			i-cache-line-size = <0x40>;
			device_type = "cpu";
			compatible = "arm,cortex-a53";
			d-cache-size = <0x8000>;
			next-level-cache = <0x03>;
			i-cache-size = <0x8000>;
			reg = <0x02>;
			enable-method = "psci";
			phandle = <0x09>;
			d-cache-sets = <0x80>;
			operating-points-v2 = <0x04>;
			i-cache-sets = <0x100>;
			#cooling-cells = <0x02>;
		};

		cpu@0 {
			d-cache-line-size = <0x40>;
			cpu-supply = <0x05>;
			clocks = <0x02 0x15>;
			i-cache-line-size = <0x40>;
			device_type = "cpu";
			compatible = "arm,cortex-a53";
			d-cache-size = <0x8000>;
			next-level-cache = <0x03>;
			i-cache-size = <0x8000>;
			reg = <0x00>;
			enable-method = "psci";
			phandle = <0x07>;
			d-cache-sets = <0x80>;
			operating-points-v2 = <0x04>;
			i-cache-sets = <0x100>;
			#cooling-cells = <0x02>;
		};

		cpu@3 {
			d-cache-line-size = <0x40>;
			clocks = <0x02 0x15>;
			i-cache-line-size = <0x40>;
			device_type = "cpu";
			compatible = "arm,cortex-a53";
			d-cache-size = <0x8000>;
			next-level-cache = <0x03>;
			i-cache-size = <0x8000>;
			reg = <0x03>;
			enable-method = "psci";
			phandle = <0x0a>;
			d-cache-sets = <0x80>;
			operating-points-v2 = <0x04>;
			i-cache-sets = <0x100>;
			#cooling-cells = <0x02>;
		};
	};

	__symbols__ {
		pwm3_ph_pin = "/soc/pinctrl@300b000/pwm3-ph-pin";
		i2c3 = "/soc/i2c@5002c00";
		syscon = "/soc/syscon@3000000";
		ve_temp_critical = "/thermal-zones/ve-thermal/trips/ve-trip-0";
		ohci2 = "/soc/usb@5310400";
		ths_calibration = "/soc/efuse@3006000/thermal-sensor-calibration@14";
		wifi_pwrseq = "/wifi-pwrseq";
		emac1 = "/soc/ethernet@5030000";
		pwm4_ph_pin = "/soc/pinctrl@300b000/pwm4-ph-pin";
		axp305 = "/soc/rsb@7083000/pmic@745";
		gpadc = "/soc/adc@5070000";
		ahub_dam_plat = "/soc/ahub_dam_plat@5097000";
		ir = "/soc/ir@7040000";
		r_rsb_pins = "/soc/pinctrl@7022000/r-rsb-pins";
		crypto = "/soc/crypto@1904000";
		i2c4_ph_pins = "/soc/pinctrl@300b000/i2c4-ph-pins";
		reg_bldo1 = "/soc/rsb@7083000/pmic@745/regulators/bldo1";
		i2c1 = "/soc/i2c@5002400";
		r_i2c_pins = "/soc/pinctrl@7022000/r-i2c-pins";
		ohci0 = "/soc/usb@5101400";
		hdmi_con_in = "/connector/port/endpoint";
		display_clocks = "/soc/bus@1000000/clock@8000";
		gpu = "/soc/gpu@1800000";
		spi0 = "/soc/spi@5010000";
		uart2_pg_pins = "/soc/pinctrl@300b000/uart2-pg-pins";
		pwm1_pi_pin = "/soc/pinctrl@300b000/pwm1-pi-pin";
		uart5_pins = "/soc/pinctrl@300b000/uart5-pins";
		rmii_pins = "/soc/pinctrl@300b000/rmii-pins";
		x32clk_fanout_pin = "/soc/pinctrl@300b000/x32clk-fanout-pin";
		mmc1 = "/soc/mmc@4021000";
		r_ccu = "/soc/clock@7010000";
		hdmi_phy = "/soc/hdmi-phy@6010000";
		i2c1_pi_pins = "/soc/pinctrl@300b000/i2c1-pi-pins";
		i2c4_pg_pins = "/soc/pinctrl@300b000/i2c4-pg-pins";
		uart4 = "/soc/serial@5001000";
		tcon_top_hdmi_in = "/soc/tcon-top@6510000/ports/port@4";
		mmc2_pins = "/soc/pinctrl@300b000/mmc2-pins";
		reg_dcdcd = "/soc/rsb@7083000/pmic@745/regulators/dcdcd";
		dma = "/soc/dma-controller@3002000";
		reg_aldo2 = "/soc/rsb@7083000/pmic@745/regulators/aldo2";
		ccu = "/soc/clock@3001000";
		uart2_pg_rts_cts_pins = "/soc/pinctrl@300b000/uart2-pg-rts-cts-pins";
		tcon_tv = "/soc/lcd-controller@6515000";
		tcon_top_hdmi_out = "/soc/tcon-top@6510000/ports/port@5";
		sram_a2 = "/soc/syscon@3000000/sram@100000";
		cpu3 = "/cpus/cpu@3";
		uart2 = "/soc/serial@5000800";
		ir_rx_pin = "/soc/pinctrl@300b000/ir-rx-pin";
		rmii_phy = "/soc/ethernet@5030000/mdio/ethernet-phy@1";
		tcon_top_mixer0_in = "/soc/tcon-top@6510000/ports/port@0";
		ahub1_mach = "/soc/ahub1_mach";
		gic = "/soc/interrupt-controller@3021000";
		uart3_pi_pins = "/soc/pinctrl@300b000/uart3-pi-pins";
		mmc1_pins = "/soc/pinctrl@300b000/mmc1-pins";
		spi1_cs0_pin = "/soc/pinctrl@300b000/spi1-cs0-pin";
		mdio1 = "/soc/ethernet@5030000/mdio";
		mixer0 = "/soc/bus@1000000/mixer@100000";
		cpu1 = "/cpus/cpu@1";
		scpi_sram = "/soc/syscon@3000000/sram@100000/scpi-sram@17c00";
		uart0 = "/soc/serial@5000000";
		ehci2 = "/soc/usb@5310000";
		dump_reg = "/soc/dump_reg@20000";
		mixer0_out = "/soc/bus@1000000/mixer@100000/ports/port@1";
		r_rsb = "/soc/rsb@7083000";
		ahub_i2s2 = "/soc/ahub-i2s2@5097000";
		i2c4 = "/soc/i2c@5003000";
		pwm5_pin = "/soc/pinctrl@300b000/pwm5-pin";
		gpu_temp_critical = "/thermal-zones/gpu-thermal/trips/gpu-trip-0";
		ohci3 = "/soc/usb@5311400";
		ddr_temp_critical = "/thermal-zones/ddr-thermal/trips/ddr-trip-0";
		addr_mgt = "/soc/addr-mgt";
		spdif = "/soc/spdif@5093000";
		cpu_opp_table = "/opp-table-cpu";
		cpu_speed_grade = "/soc/efuse@3006000/cpu-speed-grade@0";
		i2c3_ph_pins = "/soc/pinctrl@300b000/i2c3-ph-pins";
		ehci0 = "/soc/usb@5101000";
		hdmi_out = "/soc/hdmi@6000000/ports/port@1";
		tcon_top_hdmi_in_tcon_tv = "/soc/tcon-top@6510000/ports/port@4/endpoint@0";
		reg_bldo2 = "/soc/rsb@7083000/pmic@745/regulators/bldo2";
		i2c2 = "/soc/i2c@5002800";
		tcon_top = "/soc/tcon-top@6510000";
		ohci1 = "/soc/usb@5200400";
		mmc0_pins = "/soc/pinctrl@300b000/mmc0-pins";
		sram_c = "/soc/syscon@3000000/sram@28000";
		emac0 = "/soc/ethernet@5020000";
		cpu_critical = "/thermal-zones/cpu-thermal/trips/cpu-trip-2";
		spi1 = "/soc/spi@5011000";
		hdmi_out_con = "/soc/hdmi@6000000/ports/port@1/endpoint";
		usbphy = "/soc/phy@5100400";
		uart2_ph_rts_cts_pins = "/soc/pinctrl@300b000/uart2-ph-rts-cts-pins";
		i2c3_pa_pins = "/soc/pinctrl@300b000/i2c3-pa-pins";
		tcon_top_mixer0_out = "/soc/tcon-top@6510000/ports/port@1";
		ahub1_plat = "/soc/ahub1_plat";
		tcon_top_mixer0_out_tcon_tv = "/soc/tcon-top@6510000/ports/port@1/endpoint@2";
		pwm1_pg_pin = "/soc/pinctrl@300b000/pwm1-pg-pin";
		de3_sram = "/soc/syscon@3000000/sram@28000/sram-section@0";
		i2c0 = "/soc/i2c@5002000";
		uart4_pi_rts_cts_pins = "/soc/pinctrl@300b000/uart4-pi-rts-cts-pins";
		mmc2 = "/soc/mmc@4022000";
		ahub1_codec = "/soc/ahub1_mach/soundcard-mach,codec";
		spi1_pins = "/soc/pinctrl@300b000/spi1-pins";
		i2c3_pg_pins = "/soc/pinctrl@300b000/i2c3-pg-pins";
		lradc = "/soc/lradc@5070800";
		spi1_cs1_pin = "/soc/pinctrl@300b000/spi1-cs1-pin";
		ahub1_cpu = "/soc/ahub1_mach/soundcard-mach,cpu";
		usbotg = "/soc/usb@5100000";
		i2s3_pins = "/soc/pinctrl@300b000/i2s3-pins";
		uart5 = "/soc/serial@5001400";
		cpu_threshold = "/thermal-zones/cpu-thermal/trips/cpu-trip-0";
		codec = "/soc/codec@05096000";
		reg_dcdce = "/soc/rsb@7083000/pmic@745/regulators/dcdce";
		osc24M = "/osc24M-clk";
		hdmi_in_tcon_top = "/soc/hdmi@6000000/ports/port@0/endpoint";
		reg_aldo3 = "/soc/rsb@7083000/pmic@745/regulators/aldo3";
		reg_vcc5v = "/vcc5v";
		tcon_tv_in = "/soc/lcd-controller@6515000/ports/port@0";
		mmc0 = "/soc/mmc@4020000";
		tcon_top_mixer0_in_mixer0 = "/soc/tcon-top@6510000/ports/port@0/endpoint@0";
		tcon_tv_out_tcon_top = "/soc/lcd-controller@6515000/ports/port@1/endpoint@1";
		i2c0_pins = "/soc/pinctrl@300b000/i2c0-pins";
		tcon_tv_out = "/soc/lcd-controller@6515000/ports/port@1";
		r_pio = "/soc/pinctrl@7022000";
		uart3 = "/soc/serial@5000c00";
		i2c2_pi_pins = "/soc/pinctrl@300b000/i2c2-pi-pins";
		tcon_top_hdmi_out_hdmi = "/soc/tcon-top@6510000/ports/port@5/endpoint";
		cpu_target = "/thermal-zones/cpu-thermal/trips/cpu-trip-1";
		sram_c1 = "/soc/syscon@3000000/sram@1a00000";
		reg_dcdcc = "/soc/rsb@7083000/pmic@745/regulators/dcdcc";
		uart1_pins = "/soc/pinctrl@300b000/uart1-pins";
		spi0_pins = "/soc/pinctrl@300b000/spi0-pins";
		ahub_dam_mach = "/soc/ahub_dam_mach";
		reg_aldo1 = "/soc/rsb@7083000/pmic@745/regulators/aldo1";
		mixer0_out_tcon_top_mixer0 = "/soc/bus@1000000/mixer@100000/ports/port@1/endpoint";
		iommu = "/soc/iommu@30f0000";
		tcon_tv_in_tcon_top_mixer0 = "/soc/lcd-controller@6515000/ports/port@0/endpoint";
		i2s2_pins = "/soc/pinctrl@300b000/i2s2-pins";
		uart1_rts_cts_pins = "/soc/pinctrl@300b000/uart1-rts-cts-pins";
		uart2_pi_pins = "/soc/pinctrl@300b000/uart2-pi-pins";
		spi0_cs0_pin = "/soc/pinctrl@300b000/spi0-cs0-pin";
		ve_sram = "/soc/syscon@3000000/sram@1a00000/sram-section@0";
		pio = "/soc/pinctrl@300b000";
		uart0_ph_pins = "/soc/pinctrl@300b000/uart0-ph-pins";
		cpu2 = "/cpus/cpu@2";
		ths = "/soc/thermal-sensor@5070400";
		uart1 = "/soc/serial@5000400";
		ehci3 = "/soc/usb@5311000";
		hdmi = "/soc/hdmi@6000000";
		r_i2c = "/soc/i2c@7081400";
		hdmi_in = "/soc/hdmi@6000000/ports/port@0";
		pwm1_ph_pin = "/soc/pinctrl@300b000/pwm1-ph-pin";
		l2_cache = "/cpus/l2-cache";
		ext_rgmii_pins = "/soc/pinctrl@300b000/rgmii-pins";
		ahub_i2s3 = "/soc/ahub-i2s3@5097000";
		reg_dcdca = "/soc/rsb@7083000/pmic@745/regulators/dcdca";
		spdif_tx_pin = "/soc/pinctrl@300b000/spdif-tx-pin";
		de = "/display-engine";
		nmi_intc = "/soc/interrupt-controller@7010320";
		i2c2_ph_pins = "/soc/pinctrl@300b000/i2c2-ph-pins";
		pwm2_ph_pin = "/soc/pinctrl@300b000/pwm2-ph-pin";
		rtc = "/soc/rtc@7000000";
		watchdog = "/soc/watchdog@30090a0";
		mdio0 = "/soc/ethernet@5020000/mdio";
		prcm_ppu = "/soc/power-controller@7010250";
		uart4_pi_pins = "/soc/pinctrl@300b000/uart4-pi-pins";
		cpu0 = "/cpus/cpu@0";
		sid = "/soc/efuse@3006000";
		ehci1 = "/soc/usb@5200000";
		ahub_i2s1 = "/soc/ahub-i2s1@5097000";
		uart2_ph_pins = "/soc/pinctrl@300b000/uart2-ph-pins";
	};

	reserved-memory {
		#address-cells = <0x02>;
		#size-cells = <0x02>;
		ranges;

		secmon@40000000 {
			reg = <0x00 0x40000000 0x00 0x80000>;
			no-map;
		};
	};

	memory {
		device_type = "memory";
		reg = <0x00 0x40000000 0x01 0x00>;
	};
};
